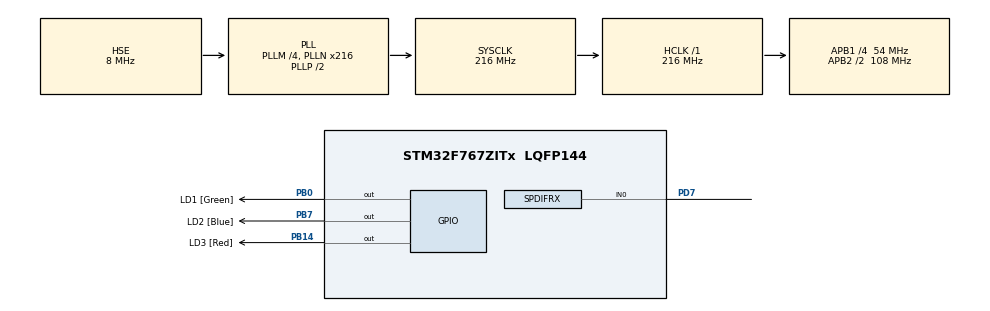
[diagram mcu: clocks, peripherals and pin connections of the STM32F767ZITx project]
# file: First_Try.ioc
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CORTEX_M7.default_mode_Activation=1
Dma.Request0=SPDIF_RX_CS
Dma.Request1=SPDIF_RX_DT
Dma.SPDIF_RX_CS.0.Direction=DMA_PERIPH_TO_MEMORY
Dma.SPDIF_RX_CS.0.FIFOMode=DMA_FIFOMODE_DISABLE
Dma.SPDIF_RX_CS.0.Instance=DMA1_Stream6
Dma.SPDIF_RX_CS.0.MemDataAlignment=DMA_MDATAALIGN_WORD
Dma.SPDIF_RX_CS.0.MemInc=DMA_MINC_ENABLE
Dma.SPDIF_RX_CS.0.Mode=DMA_NORMAL
Dma.SPDIF_RX_CS.0.PeriphDataAlignment=DMA_PDATAALIGN_WORD
Dma.SPDIF_RX_CS.0.PeriphInc=DMA_PINC_DISABLE
Dma.SPDIF_RX_CS.0.Priority=DMA_PRIORITY_LOW
Dma.SPDIF_RX_DT.1.Direction=DMA_PERIPH_TO_MEMORY
Dma.SPDIF_RX_DT.1.FIFOMode=DMA_FIFOMODE_DISABLE
Dma.SPDIF_RX_DT.1.Instance=DMA1_Stream1
Dma.SPDIF_RX_DT.1.MemDataAlignment=DMA_MDATAALIGN_WORD
Dma.SPDIF_RX_DT.1.MemInc=DMA_MINC_ENABLE
Dma.SPDIF_RX_DT.1.Mode=DMA_NORMAL
Dma.SPDIF_RX_DT.1.PeriphDataAlignment=DMA_PDATAALIGN_WORD
Dma.SPDIF_RX_DT.1.PeriphInc=DMA_PINC_DISABLE
Dma.SPDIF_RX_DT.1.Priority=DMA_PRIORITY_LOW
Mcu.Family=STM32F7
Mcu.Name=STM32F767ZITx
Mcu.Package=LQFP144
NVIC.DMA1_Stream1_IRQn=true\:0\:0\:false\:false\:true\:false\:true\:true
NVIC.DMA1_Stream6_IRQn=true\:0\:0\:false\:false\:true\:false\:true\:true
NVIC.PriorityGroup=NVIC_PRIORITYGROUP_4
PB0.GPIO_Label=LD1 [Green]
PB0.Signal=GPIO_Output
PB14.GPIO_Label=LD3 [Red]
PB14.Signal=GPIO_Output
PB7.GPIO_Label=LD2 [Blue]
PB7.Signal=GPIO_Output
PD7.Mode=IN0
PD7.Signal=SPDIFRX_IN0
PH0/OSC_IN.Mode=HSE-External-Clock-Source
PH0/OSC_IN.Signal=RCC_OSC_IN
PH1/OSC_OUT.Mode=HSE-External-Clock-Source
PH1/OSC_OUT.Signal=RCC_OSC_OUT
ProjectManager.HeapSize=0x200
ProjectManager.StackSize=0x400
ProjectManager.TargetToolchain=MDK-ARM V5.32
RCC.AHBFreq_Value=216000000
RCC.APB1CLKDivider=RCC_HCLK_DIV4
RCC.APB1Freq_Value=54000000
RCC.APB1TimFreq_Value=108000000
RCC.APB2CLKDivider=RCC_HCLK_DIV2
RCC.APB2Freq_Value=108000000
RCC.APB2TimFreq_Value=216000000
RCC.CortexFreq_Value=216000000
RCC.HCLKFreq_Value=216000000
RCC.HSE_VALUE=8000000
RCC.HSI_VALUE=16000000
RCC.LSE_VALUE=32768
RCC.PLLM=4
RCC.PLLN=216
RCC.PLLSourceVirtual=RCC_PLLSOURCE_HSE
RCC.SYSCLKFreq_VALUE=216000000
RCC.SYSCLKSource=RCC_SYSCLKSOURCE_PLLCLK
RCC.USBFreq_Value=216000000
RCC.VCOOutputFreq_Value=432000000
SPDIFRX.ChannelStatusMask=SPDIFRX_CHANNELSTATUS_ON
SPDIFRX.DataFormat=SPDIFRX_DATAFORMAT_32BITS
SPDIFRX.ParityErrorMask=SPDIFRX_PARITYERRORMASK_ON
SPDIFRX.PreambleTypeMask=SPDIFRX_PREAMBLETYPEMASK_ON
SPDIFRX.Retries=SPDIFRX_MAXRETRIES_15
SPDIFRX.StereoMode=SPDIFRX_STEREOMODE_ENABLE
SPDIFRX.ValidityBitMask=SPDIFRX_VALIDITYMASK_ON
SPDIFRX.WaitForActivity=SPDIFRX_WAITFORACTIVITY_ON
board=custom

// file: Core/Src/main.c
/* USER CODE BEGIN Header */
/**
  ******************************************************************************
  * @file           : main.c
  * @brief          : Main program body
  ******************************************************************************
  * @attention
  *
  * Copyright (c) 2022 STMicroelectronics.
  * All rights reserved.
  *
  * This software is licensed under terms that can be found in the LICENSE file
  * in the root directory of this software component.
  * If no LICENSE file comes with this software, it is provided AS-IS.
  *
  ******************************************************************************
  */
/* USER CODE END Header */
#include "main.h"

/* USER CODE BEGIN PD */

#define BUF_SIZE      4096

/* USER CODE END PD */

SPDIFRX_HandleTypeDef hspdif;
DMA_HandleTypeDef hdma_spdif_rx_cs;
DMA_HandleTypeDef hdma_spdif_rx_dt;

/* USER CODE BEGIN PV */
__IO uint32_t               RX_Data_Buf[BUF_SIZE];
__IO uint32_t               RX_Control_Buf[BUF_SIZE];
/* USER CODE END PV */

void SystemClock_Config(void);
static void MPU_Config(void);
static void MX_GPIO_Init(void);
static void MX_DMA_Init(void);
static void MX_SPDIFRX_Init(void);

int main(void)
{

  /* MPU Configuration--------------------------------------------------------*/
  MPU_Config();

  /* MCU Configuration--------------------------------------------------------*/

  /* Reset of all peripherals, Initializes the Flash interface and the Systick. */
  HAL_Init();

  /* Configure the system clock */
  SystemClock_Config();

  /* Initialize all configured peripherals */
  MX_GPIO_Init();
  MX_DMA_Init();
  MX_SPDIFRX_Init();
  /* USER CODE BEGIN 2 */

	/* Initialize buffers */
  for(uint32_t j = 0; j<BUF_SIZE; j++)
  {
    RX_Data_Buf[j] = 0;
		RX_Control_Buf[j] = 0;
  }

	/* Start SPDIFRX audio Reception in DMA circular mode */
  HAL_SPDIFRX_ReceiveDataFlow_DMA(&hspdif, (uint32_t *)RX_Data_Buf, BUF_SIZE);
	HAL_SPDIFRX_ReceiveControlFlow_DMA(&hspdif, (uint32_t *)RX_Control_Buf, BUF_SIZE);

  if(hspdif.ErrorCode != HAL_SPDIFRX_ERROR_NONE)
  {
    Error_Handler();
  }

  /* USER CODE END 2 */

  /* Infinite loop */
  /* USER CODE BEGIN WHILE */
  while (1)
  {
		HAL_GPIO_TogglePin(LD1_GPIO_Port, LD1_Pin);
		HAL_Delay(1000);
    /* USER CODE END WHILE */

  }
}

void SystemClock_Config(void)
{
  RCC_OscInitTypeDef RCC_OscInitStruct = {0};
  RCC_ClkInitTypeDef RCC_ClkInitStruct = {0};

  /** Configure the main internal regulator output voltage
  */
  __HAL_RCC_PWR_CLK_ENABLE();
  __HAL_PWR_VOLTAGESCALING_CONFIG(PWR_REGULATOR_VOLTAGE_SCALE1);

  /** Initializes the RCC Oscillators according to the specified parameters
  * in the RCC_OscInitTypeDef structure.
  */
  RCC_OscInitStruct.OscillatorType = RCC_OSCILLATORTYPE_HSE;
  RCC_OscInitStruct.HSEState = RCC_HSE_BYPASS;
  RCC_OscInitStruct.PLL.PLLState = RCC_PLL_ON;
  RCC_OscInitStruct.PLL.PLLSource = RCC_PLLSOURCE_HSE;
  RCC_OscInitStruct.PLL.PLLM = 4;
  RCC_OscInitStruct.PLL.PLLN = 216;
  RCC_OscInitStruct.PLL.PLLP = RCC_PLLP_DIV2;
  RCC_OscInitStruct.PLL.PLLQ = 2;
  RCC_OscInitStruct.PLL.PLLR = 2;
  if (HAL_RCC_OscConfig(&RCC_OscInitStruct) != HAL_OK)
  {
    Error_Handler();
  }

  /** Activate the Over-Drive mode
  */
  if (HAL_PWREx_EnableOverDrive() != HAL_OK)
  {
    Error_Handler();
  }

  /** Initializes the CPU, AHB and APB buses clocks
  */
  RCC_ClkInitStruct.ClockType = RCC_CLOCKTYPE_HCLK|RCC_CLOCKTYPE_SYSCLK
                              |RCC_CLOCKTYPE_PCLK1|RCC_CLOCKTYPE_PCLK2;
  RCC_ClkInitStruct.SYSCLKSource = RCC_SYSCLKSOURCE_PLLCLK;
  RCC_ClkInitStruct.AHBCLKDivider = RCC_SYSCLK_DIV1;
  RCC_ClkInitStruct.APB1CLKDivider = RCC_HCLK_DIV4;
  RCC_ClkInitStruct.APB2CLKDivider = RCC_HCLK_DIV2;

  if (HAL_RCC_ClockConfig(&RCC_ClkInitStruct, FLASH_LATENCY_7) != HAL_OK)
  {
    Error_Handler();
  }
}

static void MX_SPDIFRX_Init(void)
{

  hspdif.Instance = SPDIFRX;
  hspdif.Init.InputSelection = SPDIFRX_INPUT_IN0;
  hspdif.Init.Retries = SPDIFRX_MAXRETRIES_15;
  hspdif.Init.WaitForActivity = SPDIFRX_WAITFORACTIVITY_ON;
  hspdif.Init.ChannelSelection = SPDIFRX_CHANNEL_A;
  hspdif.Init.DataFormat = SPDIFRX_DATAFORMAT_32BITS;
  hspdif.Init.StereoMode = SPDIFRX_STEREOMODE_ENABLE;
  hspdif.Init.PreambleTypeMask = SPDIFRX_PREAMBLETYPEMASK_ON;
  hspdif.Init.ChannelStatusMask = SPDIFRX_CHANNELSTATUS_ON;
  hspdif.Init.ValidityBitMask = SPDIFRX_VALIDITYMASK_ON;
  hspdif.Init.ParityErrorMask = SPDIFRX_PARITYERRORMASK_ON;
  if (HAL_SPDIFRX_Init(&hspdif) != HAL_OK)
  {
    Error_Handler();
  }

}

static void MX_DMA_Init(void)
{

  /* DMA controller clock enable */
  __HAL_RCC_DMA1_CLK_ENABLE();

  /* DMA interrupt init */
  /* DMA1_Stream1_IRQn interrupt configuration */
  HAL_NVIC_SetPriority(DMA1_Stream1_IRQn, 0, 0);
  HAL_NVIC_EnableIRQ(DMA1_Stream1_IRQn);
  /* DMA1_Stream6_IRQn interrupt configuration */
  HAL_NVIC_SetPriority(DMA1_Stream6_IRQn, 0, 0);
  HAL_NVIC_EnableIRQ(DMA1_Stream6_IRQn);

}

static void MX_GPIO_Init(void)
{
  GPIO_InitTypeDef GPIO_InitStruct = {0};

  /* GPIO Ports Clock Enable */
  __HAL_RCC_GPIOH_CLK_ENABLE();
  __HAL_RCC_GPIOB_CLK_ENABLE();
  __HAL_RCC_GPIOD_CLK_ENABLE();

  /*Configure GPIO pin Output Level */
  HAL_GPIO_WritePin(GPIOB, LD1_Pin|LD3_Pin|LD2_Pin, GPIO_PIN_RESET);

  /*Configure GPIO pins : LD1_Pin LD3_Pin LD2_Pin */
  GPIO_InitStruct.Pin = LD1_Pin|LD3_Pin|LD2_Pin;
  GPIO_InitStruct.Mode = GPIO_MODE_OUTPUT_PP;
  GPIO_InitStruct.Pull = GPIO_NOPULL;
  GPIO_InitStruct.Speed = GPIO_SPEED_FREQ_LOW;
  HAL_GPIO_Init(GPIOB, &GPIO_InitStruct);

}

/* MPU Configuration */

void MPU_Config(void)
{
  MPU_Region_InitTypeDef MPU_InitStruct = {0};

  /* Disables the MPU */
  HAL_MPU_Disable();

  /** Initializes and configures the Region and the memory to be protected
  */
  MPU_InitStruct.Enable = MPU_REGION_ENABLE;
  MPU_InitStruct.Number = MPU_REGION_NUMBER0;
  MPU_InitStruct.BaseAddress = 0x0;
  MPU_InitStruct.Size = MPU_REGION_SIZE_4GB;
  MPU_InitStruct.SubRegionDisable = 0x87;
  MPU_InitStruct.TypeExtField = MPU_TEX_LEVEL0;
  MPU_InitStruct.AccessPermission = MPU_REGION_NO_ACCESS;
  MPU_InitStruct.DisableExec = MPU_INSTRUCTION_ACCESS_DISABLE;
  MPU_InitStruct.IsShareable = MPU_ACCESS_SHAREABLE;
  MPU_InitStruct.IsCacheable = MPU_ACCESS_NOT_CACHEABLE;
  MPU_InitStruct.IsBufferable = MPU_ACCESS_NOT_BUFFERABLE;

  HAL_MPU_ConfigRegion(&MPU_InitStruct);
  /* Enables the MPU */
  HAL_MPU_Enable(MPU_PRIVILEGED_DEFAULT);

}

void Error_Handler(void)
{
  /* USER CODE BEGIN Error_Handler_Debug */
  /* User can add his own implementation to report the HAL error return state */
  __disable_irq();

	/* RED LED On in error case */
  HAL_GPIO_WritePin(LD3_GPIO_Port, LD3_Pin, GPIO_PIN_SET);

    while (1)
  {
  }
  /* USER CODE END Error_Handler_Debug */
}
